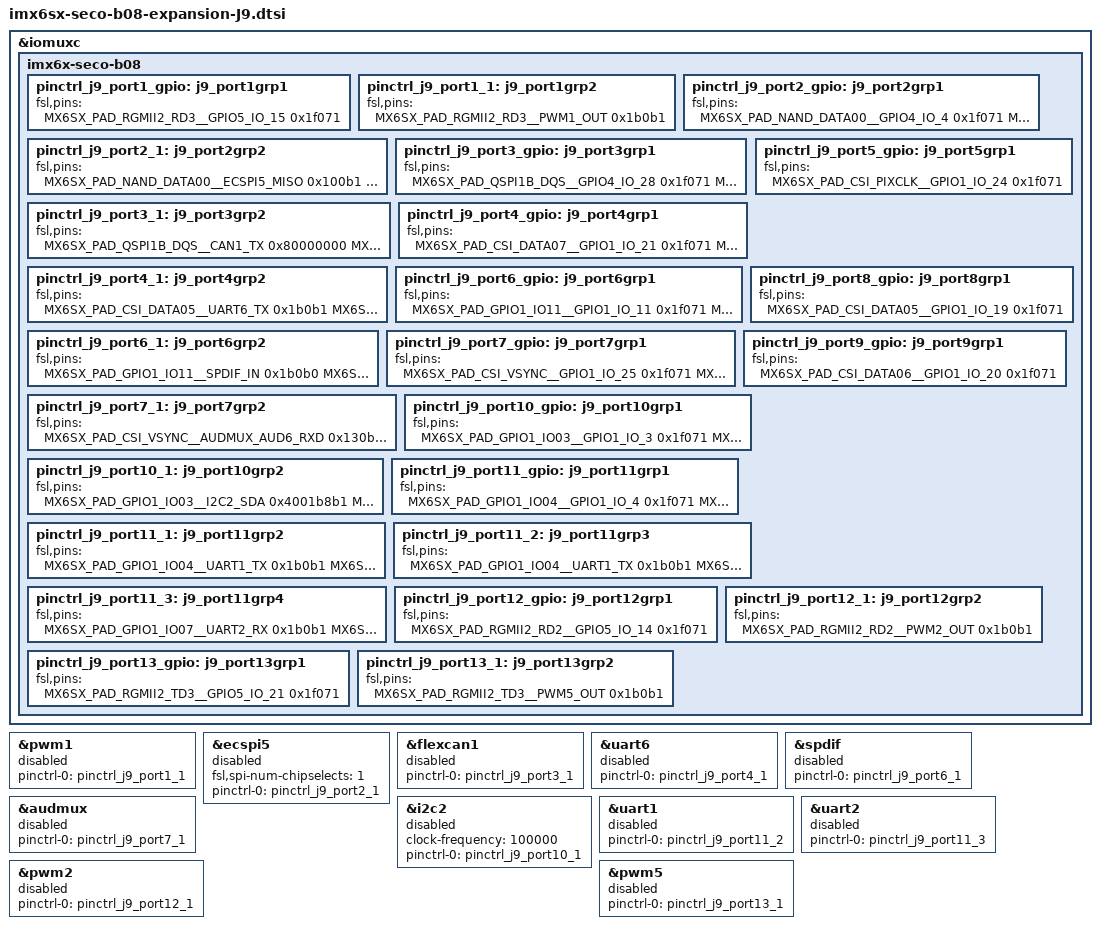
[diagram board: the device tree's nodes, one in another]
/*
 * Copyright 2012 Freescale Semiconductor, Inc.
 * Copyright 2011 Linaro Ltd.
 *
 * The code contained herein is licensed under the GNU General Public
 * License. You may obtain a copy of the GNU General Public License
 * Version 2 or later at the following locations:
 *
 * http://www.opensource.org/licenses/gpl-license.html
 * http://www.gnu.org/copyleft/gpl.html
 */

#include <dt-bindings/input/input.h>
#include <dt-bindings/gpio/gpio.h>


/*  __________________________________________________________________________
 * |                                                                          |
 * |                            IOMUX EXPANSION J9                            |
 * |__________________________________________________________________________|
 */
/// {
&iomuxc {

	imx6x-seco-b08 {

/*  ____________________________________________________________________________
 * |__________________________________ PORT1 ___________________________________|
*/

		pinctrl_j9_port1_gpio: j9_port1grp1 {
			fsl,pins = <
				MX6SX_PAD_RGMII2_RD3__GPIO5_IO_15	0x1f071
			>;
		};
	
		pinctrl_j9_port1_1: j9_port1grp2 {	/* PWM1 */
			fsl,pins = <
				MX6SX_PAD_RGMII2_RD3__PWM1_OUT		0x1b0b1
			>;
		};

/*  ____________________________________________________________________________
 * |__________________________________ PORT2 ___________________________________|
*/

		pinctrl_j9_port2_gpio: j9_port2grp1 {
			fsl,pins = <
				MX6SX_PAD_NAND_DATA00__GPIO4_IO_4	0x1f071
                                MX6SX_PAD_NAND_DATA01__GPIO4_IO_5	0x1f071
                                MX6SX_PAD_NAND_DATA02__GPIO4_IO_6	0x1f071
                                MX6SX_PAD_NAND_DATA03__GPIO4_IO_7 	0x1f071
			>;
		};
	
		pinctrl_j9_port2_1: j9_port2grp2 {
                        fsl,pins = <
                                MX6SX_PAD_NAND_DATA00__ECSPI5_MISO 	0x100b1
                                MX6SX_PAD_NAND_DATA01__ECSPI5_MOSI	0x100b1
                                MX6SX_PAD_NAND_DATA02__ECSPI5_SCLK	0x100b1
                                MX6SX_PAD_NAND_DATA03__ECSPI5_SS0	0x100b1
                        >;
                };

/*  ____________________________________________________________________________
 * |__________________________________ PORT3 ___________________________________|
*/

		pinctrl_j9_port3_gpio: j9_port3grp1 {
			fsl,pins = <
				MX6SX_PAD_QSPI1B_DQS__GPIO4_IO_28       0x1f071
                                MX6SX_PAD_QSPI1A_SS1_B__GPIO4_IO_23     0x1f071
			>;
		};

		pinctrl_j9_port3_1: j9_port3grp2 {
                        fsl,pins = <
                                MX6SX_PAD_QSPI1B_DQS__CAN1_TX           0x80000000
                                MX6SX_PAD_QSPI1A_SS1_B__CAN1_RX         0x80000000
                        >;
                };

/*  ____________________________________________________________________________
 * |__________________________________ PORT4 ___________________________________|
*/

		pinctrl_j9_port4_gpio: j9_port4grp1 {
			fsl,pins = <
				MX6SX_PAD_CSI_DATA07__GPIO1_IO_21       0x1f071
				MX6SX_PAD_CSI_DATA06__GPIO1_IO_20       0x1f071
				MX6SX_PAD_CSI_DATA05__GPIO1_IO_19       0x1f071
				MX6SX_PAD_CSI_DATA04__GPIO1_IO_18       0x1f071
			>;
		};
		pinctrl_j9_port4_1: j9_port4grp2 {
			fsl,pins = <
				MX6SX_PAD_CSI_DATA05__UART6_TX          0x1b0b1
				MX6SX_PAD_CSI_DATA04__UART6_RX          0x1b0b1
				MX6SX_PAD_CSI_DATA07__UART6_CTS_B	0x1b0b1
				MX6SX_PAD_CSI_DATA06__UART6_RTS_B	0x1b0b1
			>;
		};

/*  ____________________________________________________________________________
 * |__________________________________ PORT5 ___________________________________|
*/

		pinctrl_j9_port5_gpio: j9_port5grp1 {
			fsl,pins = <
				MX6SX_PAD_CSI_PIXCLK__GPIO1_IO_24	0x1f071 
			>;
		};

/*  ____________________________________________________________________________
 * |__________________________________ PORT6 ___________________________________|
*/

		pinctrl_j9_port6_gpio: j9_port6grp1 {
			fsl,pins = <
				MX6SX_PAD_GPIO1_IO11__GPIO1_IO_11	0x1f071
				MX6SX_PAD_GPIO1_IO12__GPIO1_IO_12	0x1f071
			>;
		};

		pinctrl_j9_port6_1: j9_port6grp2 {
			fsl,pins = <
				MX6SX_PAD_GPIO1_IO11__SPDIF_IN		0x1b0b0
				MX6SX_PAD_GPIO1_IO12__SPDIF_OUT		0x1b0b0
			>;
		};

/*  ____________________________________________________________________________
 * |__________________________________ PORT7 ___________________________________|
*/

		pinctrl_j9_port7_gpio: j9_port7grp1 {
			fsl,pins = <
				MX6SX_PAD_CSI_VSYNC__GPIO1_IO_25	0x1f071		
				MX6SX_PAD_CSI_HSYNC__GPIO1_IO_22	0x1f071		
				MX6SX_PAD_CSI_DATA00__GPIO1_IO_14	0x1f071		
				MX6SX_PAD_CSI_DATA01__GPIO1_IO_15	0x1f071	
			>;
		};

	 	pinctrl_j9_port7_1: j9_port7grp2 {
                        fsl,pins = <
				MX6SX_PAD_CSI_VSYNC__AUDMUX_AUD6_RXD		0x130b0		// {{external-gpio-24}}
				MX6SX_PAD_CSI_HSYNC__AUDMUX_AUD6_TXD		0x120b0		// {{external-gpio-25}}
				MX6SX_PAD_CSI_DATA00__AUDMUX_AUD6_TXC		0x130b0		// {{external-gpio-26}}
				MX6SX_PAD_CSI_DATA01__AUDMUX_AUD6_TXFS		0x130b0		// {{external-gpio-27}}
                        >;
                };

/*  ____________________________________________________________________________
 * |__________________________________ PORT8 ___________________________________|
*/

		pinctrl_j9_port8_gpio: j9_port8grp1 {
			fsl,pins = <
				MX6SX_PAD_CSI_DATA05__GPIO1_IO_19	0x1f071
			>;
		};
	

/*  ____________________________________________________________________________
 * |__________________________________ PORT9 ___________________________________|
*/

		pinctrl_j9_port9_gpio: j9_port9grp1 {
			fsl,pins = <
				MX6SX_PAD_CSI_DATA06__GPIO1_IO_20	0x1f071
			>;
		};

/*  ____________________________________________________________________________
 * |__________________________________ PORT10 ___________________________________|
*/

		pinctrl_j9_port10_gpio: j9_port10grp1 {
			fsl,pins = <
				MX6SX_PAD_GPIO1_IO03__GPIO1_IO_3        0x1f071
				MX6SX_PAD_GPIO1_IO02__GPIO1_IO_2        0x1f071
			>;
		};

		pinctrl_j9_port10_1: j9_port10grp2 {
			fsl,pins = <
				MX6SX_PAD_GPIO1_IO03__I2C2_SDA          0x4001b8b1
				MX6SX_PAD_GPIO1_IO02__I2C2_SCL          0x4001b8b1
			>;
		};

/*  ____________________________________________________________________________
 * |__________________________________ PORT11 ___________________________________|
*/

		pinctrl_j9_port11_gpio: j9_port11grp1 {
			fsl,pins = <
				MX6SX_PAD_GPIO1_IO04__GPIO1_IO_4        0x1f071
				MX6SX_PAD_GPIO1_IO05__GPIO1_IO_5        0x1f071
				MX6SX_PAD_GPIO1_IO07__GPIO1_IO_7        0x1f071
				MX6SX_PAD_GPIO1_IO06__GPIO1_IO_6        0x1f071
			>;
		};

		pinctrl_j9_port11_1: j9_port11grp2 {
			fsl,pins = <
				MX6SX_PAD_GPIO1_IO04__UART1_TX          0x1b0b1
				MX6SX_PAD_GPIO1_IO05__UART1_RX          0x1b0b1
				MX6SX_PAD_GPIO1_IO07__UART1_CTS_B	0x1b0b1
				MX6SX_PAD_GPIO1_IO06__UART1_RTS_B	0x1b0b1
			>;
		};

		pinctrl_j9_port11_2: j9_port11grp3 {
			fsl,pins = <
				MX6SX_PAD_GPIO1_IO04__UART1_TX          0x1b0b1
				MX6SX_PAD_GPIO1_IO05__UART1_RX          0x1b0b1
			>;
		};
	
		pinctrl_j9_port11_3: j9_port11grp4 {
			fsl,pins = <
				MX6SX_PAD_GPIO1_IO07__UART2_RX          0x1b0b1
				MX6SX_PAD_GPIO1_IO06__UART2_TX          0x1b0b1
			>;
		};
	
/*  ____________________________________________________________________________
 * |__________________________________ PORT12 ___________________________________|
*/

		pinctrl_j9_port12_gpio: j9_port12grp1 {
			fsl,pins = <
				MX6SX_PAD_RGMII2_RD2__GPIO5_IO_14	0x1f071
			>;
		};

		pinctrl_j9_port12_1: j9_port12grp2 {	/* PWM2 */
			fsl,pins = <
				MX6SX_PAD_RGMII2_RD2__PWM2_OUT		0x1b0b1
			>;
		};

/*  ____________________________________________________________________________
 * |__________________________________ PORT13 ___________________________________|
*/

		pinctrl_j9_port13_gpio: j9_port13grp1 {
			fsl,pins = <
				MX6SX_PAD_RGMII2_TD3__GPIO5_IO_21 	0x1f071
			>;
		};
		pinctrl_j9_port13_1: j9_port13grp2 {	/* PWM5 */
			fsl,pins = <
				MX6SX_PAD_RGMII2_TD3__PWM5_OUT		0x1b0b1
			>;
		};

	};

};

/*  __________________________________________________________________________
 * |__________________________________________________________________________|
 */


/*  ____________________________________________________________________________
 * |___________________________________ PORT1 __________________________________|
*/

&pwm1 {
	pinctrl-names = "default";
	pinctrl-0     = <&pinctrl_j9_port1_1>;
	status        = "disabled";
};

/*  ____________________________________________________________________________
 * |___________________________________ PORT2 __________________________________|
*/

&ecspi5 {
        fsl,spi-num-chipselects = <1>;
        pinctrl-names = "default";
        pinctrl-0 = <&pinctrl_j9_port2_1>;
        status = "disabled"; 
};

/*  ____________________________________________________________________________
 * |___________________________________ PORT3 __________________________________|
*/

&flexcan1 {
        pinctrl-names = "default";
        pinctrl-0 = <&pinctrl_j9_port3_1>;
        status = "disabled";
};

/*  ____________________________________________________________________________
 * |___________________________________ PORT4 __________________________________|
*/

&uart6 {
	pinctrl-names = "default";
	pinctrl-0 = <&pinctrl_j9_port4_1>;
	status = "disabled";
};

/*  ____________________________________________________________________________
 * |___________________________________ PORT6 __________________________________|
*/

&spdif {
   	pinctrl-names = "default";
   	pinctrl-0 = <&pinctrl_j9_port6_1>;
   	status = "disabled";
};

/*  ____________________________________________________________________________
 * |___________________________________ PORT7 __________________________________|
*/
&audmux {
	pinctrl-names = "default";
	pinctrl-0 = <&pinctrl_j9_port7_1>;	
	status="disabled";
};

/*  ____________________________________________________________________________
 * |___________________________________ PORT10 __________________________________|
*/

&i2c2 {
	clock-frequency = <100000>;
	pinctrl-names = "default";
	pinctrl-0 = <&pinctrl_j9_port10_1>;
	status = "disabled";
};

/*  ____________________________________________________________________________
 * |___________________________________ PORT11 __________________________________|
*/

&uart1 {
	pinctrl-names = "default";
	pinctrl-0 = <&pinctrl_j9_port11_1>;
	status = "disabled";
};

&uart1 {
	pinctrl-names = "default";
	pinctrl-0 = <&pinctrl_j9_port11_2>;
	status = "disabled";
};


&uart2 {
	pinctrl-names = "default";
	pinctrl-0 = <&pinctrl_j9_port11_3>;
	status = "disabled";
};

/*  ____________________________________________________________________________
 * |___________________________________ PORT12 __________________________________|
*/

&pwm2 {
	pinctrl-names = "default";
	pinctrl-0     = <&pinctrl_j9_port12_1>;
	status        = "disabled";
};

/*  ____________________________________________________________________________
 * |___________________________________ PORT12 __________________________________|
*/

&pwm5 {
	pinctrl-names = "default";
	pinctrl-0     = <&pinctrl_j9_port13_1>;
	status        = "disabled";
};



